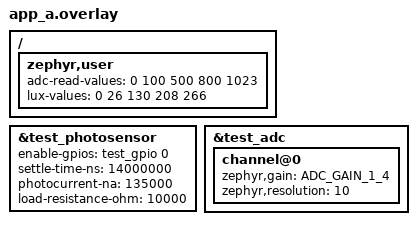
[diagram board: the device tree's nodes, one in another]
/*
 * Copyright (c) 2026 Nordic Semiconductor ASA
 *
 * SPDX-License-Identifier: Apache-2.0
 */

#include "common.overlay"

/*
 * All units in formula are SI units or unitless.
 *
 * lux = ((((vref / gain) / ((2 ** resolution) - 1)) * adc_read_value) / resistance) /
 *       (photocurrent / 100)
 */

/ {
	zephyr,user {
		adc-read-values = <0 100 500 800 1023>;
		lux-values = <0 26 130 208 266>;
	};
};

&test_photosensor {
	enable-gpios = <&test_gpio 0 GPIO_ACTIVE_HIGH>;
	settle-time-ns = <14000000>;
	photocurrent-na = <135000>;
	load-resistance-ohm = <10000>;
};

&test_adc {
	channel@0 {
		zephyr,gain = "ADC_GAIN_1_4";
		zephyr,resolution = <10>;
	};
};
